# ioextended1 register map
Registers from a debugger description file.
Registers are 8-bit, access not given, reset 0x0 unless marked. A register's access mark holds for its fields unless they carry their own. Addresses are absolute; registers are grouped by the start of their names; lines under a group give offsets from that group; [hi:lo] are bit positions; {n}, {i} and the like mark numbered series; 'fields as' and 'values as' point back to an identical list; <NAME> marks a mode.

## Further device data
interrupts=NMI 0x00 1; extern0 0x03 2 IE.EX0 TCON.IE0; timer0 0x0B 2 IE.ET0 TCON.TF0; extern1 0x13 2 IE.EX1 TCON.IE1; timer1 0x1B 2 IE.ET1 TCON.TF1; sio_ti 0x23 2 IE.ES SCON.TI; sio_ri 0x23 2 IE.ES SCON.RI

## SFR
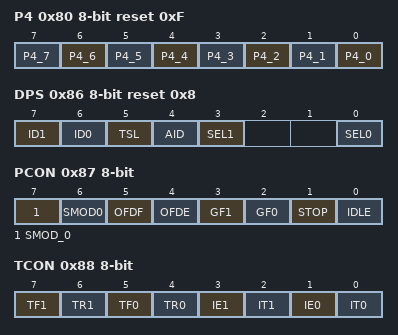
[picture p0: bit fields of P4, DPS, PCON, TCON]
0x80 P4 reset 0xF — Port 4
  [n] P4_{n} (n=0..7)
0x82 DPL — Data Pointer Low 0
0x83 DPH — Data Pointer High 0
0x86 DPS reset 0x8 — Data Pointer Select
  [7] ID1, [6] ID0, [5] TSL, [4] AID, [3] SEL1, [0] SEL0
0x87 PCON — Power Control
  [7] SMOD_0, [6] SMOD0, [5] OFDF, [4] OFDE, [3] GF1, [2] GF0, [1] STOP, [0] IDLE
0x88 TCON — Timer/Counter Control
  [7] TF1, [6] TR1, [5] TF0, [4] TR0, [3] IE1, [2] IT1, [1] IE0, [0] IT0
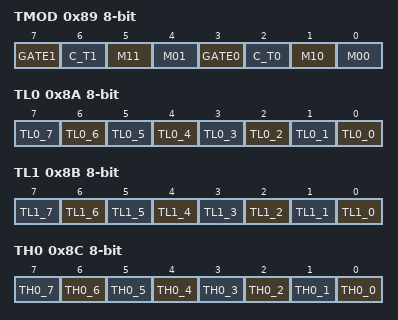
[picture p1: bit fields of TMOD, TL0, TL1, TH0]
0x89 TMOD — Timer Mode Control
  [7] GATE1, [6] C_T1, [5] M11, [4] M01, [3] GATE0, [2] C_T0, [1] M10, [0] M00
0x8A TL0 — Timer 0 LSB
  [n] TL0_{n} (n=0..7)
0x8B TL1 — Timer 1 LSB
  [n] TL1_{n} (n=0..7)
0x8C TH0 — Timer 0 MSB
  [n] TH0_{n} (n=0..7)
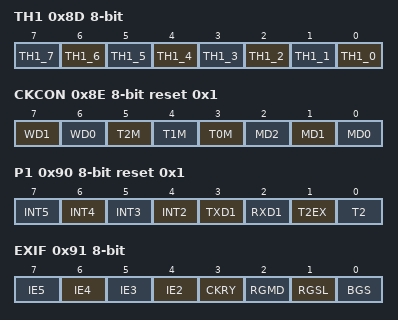
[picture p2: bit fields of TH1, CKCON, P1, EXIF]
0x8D TH1 — Timer 1 MSB
  [n] TH1_{n} (n=0..7)
0x8E CKCON reset 0x1 — Clock Control
  [7] WD1, [6] WD0, [5] T2M, [4] T1M, [3] T0M, [2] MD2, [1] MD1, [0] MD0
0x90 P1 reset 0x1 — Port 1
  [n+2] INT{n} (n=2..5), [3] TXD1, [2] RXD1, [1] T2EX, [0] T2
0x91 EXIF — External Interrupt Flag
  [n+2] IE{n} (n=2..5), [3] CKRY, [2] RGMD, [1] RGSL, [0] BGS
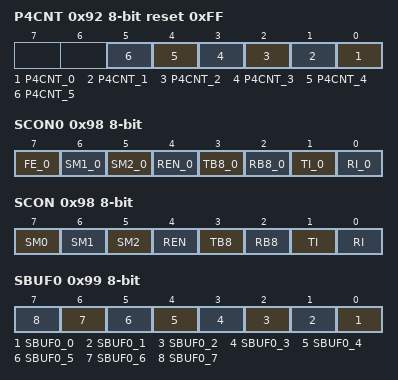
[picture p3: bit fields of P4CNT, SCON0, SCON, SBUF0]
0x92 P4CNT reset 0xFF — Port 4 Control Register
  [n] P4CNT_{n} (n=0..5)
0x93 DPX — Data Pointer Extended Register 0
0x98 SCON0 — Serial Port 0 Control
  [7] FE_0, [6] SM1_0, [5] SM2_0, [4] REN_0, [3] TB8_0, [2] RB8_0, [1] TI_0, [0] RI_0
0x98 SCON — Serial Port 0 Control
  [7] SM0, [6] SM1, [5] SM2, [4] REN, [3] TB8, [2] RB8, [1] TI, [0] RI
0x99 SBUF0 — Serial Data Buffer 0
  [n] SBUF0_{n} (n=0..7)
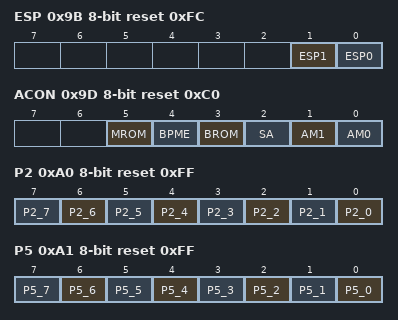
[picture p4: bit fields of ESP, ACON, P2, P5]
0x9B ESP reset 0xFC — Extended Stack Pointer Register
  [1] ESP1, [0] ESP0
0x9C AP — Address Page Register
0x9D ACON reset 0xC0 — Address Control Register
  [5] MROM, [4] BPME, [3] BROM, [2] SA, [1] AM1, [0] AM0
0xA0 P2 reset 0xFF — Port 2
  [n] P2_{n} (n=0..7)
0xA1 P5 reset 0xFF — Port 5
  [n] P5_{n} (n=0..7)
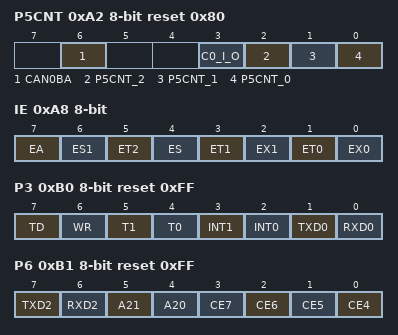
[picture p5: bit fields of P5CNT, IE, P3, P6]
0xA2 P5CNT reset 0x80 — Port 5 Control Register
  [6] CAN0BA, [3] C0_I_O, [2] P5CNT_2, [1] P5CNT_1, [0] P5CNT_0
0xA8 IE — Interrupt Enable
  [7] EA, [6] ES1, [5] ET2, [4] ES, [3] ET1, [2] EX1, [1] ET0, [0] EX0
0xB0 P3 reset 0xFF — Port 3
  [7] TD, [6] WR, [5] T1, [4] T0, [3] INT1, [2] INT0, [1] TXD0, [0] RXD0
0xB1 P6 reset 0xFF — Port 6
  [7] TXD2, [6] RXD2, [5] A21, [4] A20, [n-4] CE{n} (n=4..7)
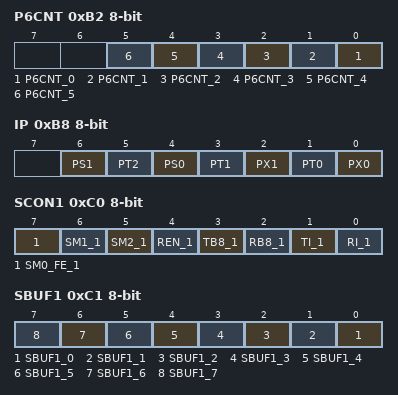
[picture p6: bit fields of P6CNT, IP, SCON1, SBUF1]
0xB2 P6CNT — Port 6 Configuration Control
  [n] P6CNT_{n} (n=0..5)
0xB8 IP — Interrupt Priority
  [6] PS1, [5] PT2, [4] PS0, [3] PT1, [2] PX1, [1] PT0, [0] PX0
0xC0 SCON1 — Serial Port Control
  [7] SM0_FE_1, [6] SM1_1, [5] SM2_1, [4] REN_1, [3] TB8_1, [2] RB8_1, [1] TI_1, [0] RI_1
0xC1 SBUF1 — Serial Data Buffer 1
  [n] SBUF1_{n} (n=0..7)
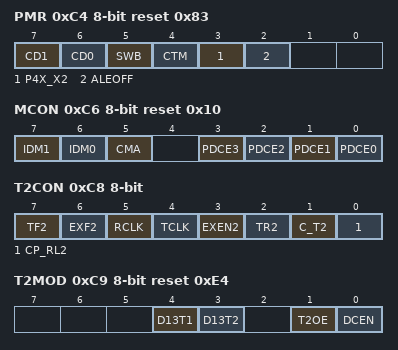
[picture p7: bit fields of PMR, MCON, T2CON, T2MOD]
0xC4 PMR reset 0x83 — Power Management Register
  [7] CD1, [6] CD0, [5] SWB, [4] CTM, [3] P4X_X2, [2] ALEOFF
0xC6 MCON reset 0x10 — Memory Control Register
  [7] IDM1, [6] IDM0, [5] CMA, [n] PDCE{n} (n=0..3)
0xC8 T2CON — Timer 2 Control
  [7] TF2, [6] EXF2, [5] RCLK, [4] TCLK, [3] EXEN2, [2] TR2, [1] C_T2, [0] CP_RL2
0xC9 T2MOD reset 0xE4 — Timer 2 Mode
  [4] D13T1, [3] D13T2, [1] T2OE, [0] DCEN
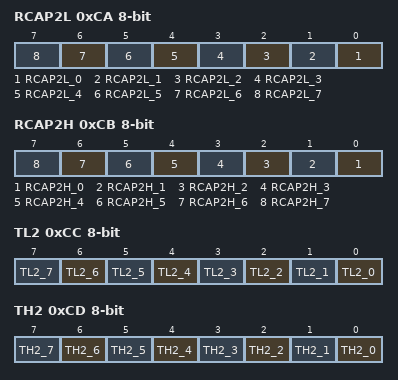
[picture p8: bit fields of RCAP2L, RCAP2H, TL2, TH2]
0xCA RCAP2L — Timer 2 Capture LSB
  [n] RCAP2L_{n} (n=0..7)
0xCB RCAP2H — Timer 2 Capture MSB
  [n] RCAP2H_{n} (n=0..7)
0xCC TL2 — Timer 2 LSB
  [n] TL2_{n} (n=0..7)
0xCD TH2 — Timer 2 MSB
  [n] TH2_{n} (n=0..7)
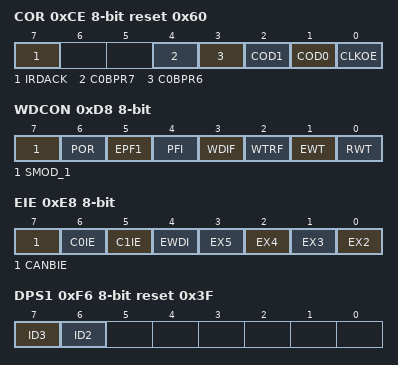
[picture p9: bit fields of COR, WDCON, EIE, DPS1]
0xCE COR reset 0x60 — Clock Output Register
  [7] IRDACK, [4] C0BPR7, [3] C0BPR6, [2] COD1, [1] COD0, [0] CLKOE
0xD8 WDCON — Watchdog Control
  [7] SMOD_1, [6] POR, [5] EPF1, [4] PFI, [3] WDIF, [2] WTRF, [1] EWT, [0] RWT
0xE8 EIE — Extended Interrupt Enable
  [7] CANBIE, [6] C0IE, [5] C1IE, [4] EWDI, [n-2] EX{n} (n=2..5)
0xEA MXAX — MOVX Extended Address Register
0xF6 DPS1 reset 0x3F — Data Pointer Select 1
  [7] ID3, [6] ID2
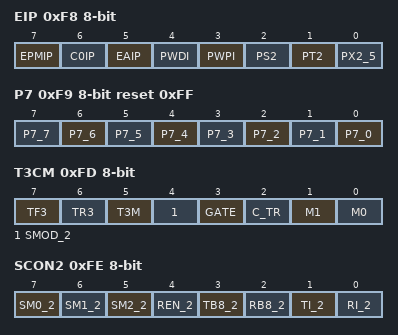
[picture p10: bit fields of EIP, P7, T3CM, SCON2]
0xF8 EIP — Extended Interrupt Priority
  [7] EPMIP, [6] C0IP, [5] EAIP, [4] PWDI, [3] PWPI, [2] PS2, [1] PT2, [0] PX2_5
0xF9 P7 reset 0xFF — Port 7
  [n] P7_{n} (n=0..7)
0xFB TL3 — Count Registers 3, LSB
0xFC TH3 — Count Registers 3, MSB
0xFD T3CM — Timer Control/Mode Registers 3
  [7] TF3, [6] TR3, [5] T3M, [4] SMOD_2, [3] GATE, [2] C_TR, [1] M1, [0] M0
0xFE SCON2 — Serial Port Control Register
  [7] SM0_2, [6] SM1_2, [5] SM2_2, [4] REN_2, [3] TB8_2, [2] RB8_2, [1] TI_2, [0] RI_2
0xFF SBUF2 — Serial Buffer 2
